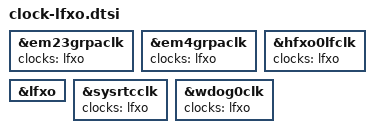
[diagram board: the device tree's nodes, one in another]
/*
 * Copyright (c) 2026 Silicon Laboratories Inc.
 *
 * SPDX-License-Identifier: Apache-2.0
 */

&em23grpaclk {
	clocks = <&lfxo>;
};

&em4grpaclk {
	clocks = <&lfxo>;
};

&hfxo0lfclk {
	clocks = <&lfxo>;
};

&lfxo {
	status = "okay";
};

&sysrtcclk {
	clocks = <&lfxo>;
};

&wdog0clk {
	clocks = <&lfxo>;
};
